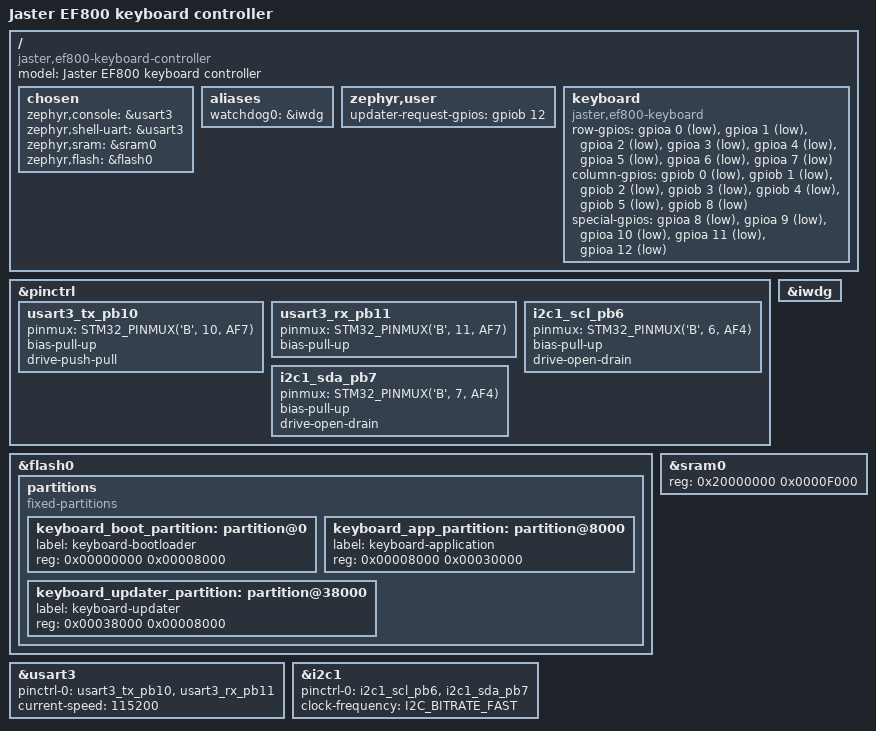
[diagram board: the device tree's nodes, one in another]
/* SPDX-License-Identifier: Apache-2.0 */

/dts-v1/;
#include <st/l4/stm32l431Xc.dtsi>
#include <zephyr/dt-bindings/gpio/gpio.h>
#include <zephyr/dt-bindings/pinctrl/stm32-pinctrl.h>

/ {
	model = "Jaster EF800 keyboard controller";
	compatible = "jaster,ef800-keyboard-controller";

	chosen {
		zephyr,console = &usart3;
		zephyr,shell-uart = &usart3;
		zephyr,sram = &sram0;
		zephyr,flash = &flash0;
	};

	aliases {
		watchdog0 = &iwdg;
	};

	zephyr,user {
		/* PB12 is pulled up; JP7 can pull it low to request the updater. */
		updater-request-gpios = <&gpiob 12 GPIO_PULL_UP>;
	};


	keyboard {
		compatible = "jaster,ef800-keyboard";
		row-gpios = <&gpioa 0 (GPIO_PULL_UP | GPIO_ACTIVE_LOW)>,
				    <&gpioa 1 (GPIO_PULL_UP | GPIO_ACTIVE_LOW)>,
				    <&gpioa 2 (GPIO_PULL_UP | GPIO_ACTIVE_LOW)>,
				    <&gpioa 3 (GPIO_PULL_UP | GPIO_ACTIVE_LOW)>,
				    <&gpioa 4 (GPIO_PULL_UP | GPIO_ACTIVE_LOW)>,
				    <&gpioa 5 (GPIO_PULL_UP | GPIO_ACTIVE_LOW)>,
				    <&gpioa 6 (GPIO_PULL_UP | GPIO_ACTIVE_LOW)>,
				    <&gpioa 7 (GPIO_PULL_UP | GPIO_ACTIVE_LOW)>;
		column-gpios = <&gpiob 0 GPIO_ACTIVE_LOW>,
					<&gpiob 1 GPIO_ACTIVE_LOW>,
					<&gpiob 2 GPIO_ACTIVE_LOW>,
					<&gpiob 3 GPIO_ACTIVE_LOW>,
					<&gpiob 4 GPIO_ACTIVE_LOW>,
					<&gpiob 5 GPIO_ACTIVE_LOW>,
					<&gpiob 8 GPIO_ACTIVE_LOW>;
		special-gpios = <&gpioa 8 (GPIO_PULL_UP | GPIO_ACTIVE_LOW)>,
						<&gpioa 9 (GPIO_PULL_UP | GPIO_ACTIVE_LOW)>,
						<&gpioa 10 (GPIO_PULL_UP | GPIO_ACTIVE_LOW)>,
						<&gpioa 11 (GPIO_PULL_UP | GPIO_ACTIVE_LOW)>,
						<&gpioa 12 (GPIO_PULL_UP | GPIO_ACTIVE_LOW)>;
		status = "okay";
	};
};

&pinctrl {
	usart3_tx_pb10: usart3_tx_pb10 {
		pinmux = <STM32_PINMUX('B', 10, AF7)>;
		bias-pull-up;
		drive-push-pull;
	};

	usart3_rx_pb11: usart3_rx_pb11 {
		pinmux = <STM32_PINMUX('B', 11, AF7)>;
		bias-pull-up;
	};
};

&flash0 {
	partitions {
		compatible = "fixed-partitions";
		#address-cells = <1>;
		#size-cells = <1>;

		keyboard_boot_partition: partition@0 {
			label = "keyboard-bootloader";
			reg = <0x00000000 0x00008000>;
		};
		keyboard_app_partition: partition@8000 {
			label = "keyboard-application";
			reg = <0x00008000 0x00030000>;
		};
		keyboard_updater_partition: partition@38000 {
			label = "keyboard-updater";
			reg = <0x00038000 0x00008000>;
		};
	};
};

&usart3 {
		pinctrl-0 = <&usart3_tx_pb10 &usart3_rx_pb11>;
		pinctrl-names = "default";
		current-speed = <115200>;
		status = "okay";
};

&iwdg {
	status = "okay";
};

/* EF800 Application I2C1 is connected to the keyboard controller on PB6/PB7. */
&pinctrl {
	i2c1_scl_pb6: i2c1_scl_pb6 {
		pinmux = <STM32_PINMUX('B', 6, AF4)>;
		bias-pull-up;
		drive-open-drain;
	};

	i2c1_sda_pb7: i2c1_sda_pb7 {
		pinmux = <STM32_PINMUX('B', 7, AF4)>;
		bias-pull-up;
		drive-open-drain;
	};
};

&i2c1 {
	pinctrl-0 = <&i2c1_scl_pb6 &i2c1_sda_pb7>;
	pinctrl-names = "default";
	clock-frequency = <I2C_BITRATE_FAST>;
	status = "okay";
};

&sram0 {
	reg = <0x20000000 0x0000F000>;
};
